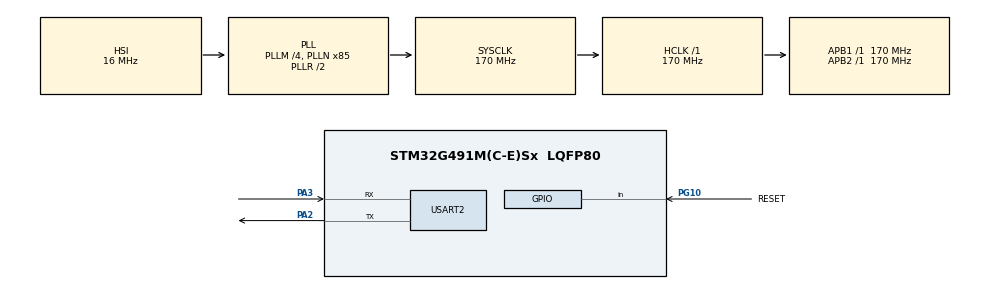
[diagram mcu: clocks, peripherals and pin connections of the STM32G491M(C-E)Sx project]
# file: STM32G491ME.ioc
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FREERTOS.Tasks01=defaultTask,0,192,StartDefaultTask,Default,NULL,Dynamic,NULL,NULL
FREERTOS.configMINIMAL_STACK_SIZE=192
FREERTOS.configTOTAL_HEAP_SIZE=65536
FREERTOS.configUSE_NEWLIB_REENTRANT=1
FREERTOS.configUSE_TIMERS=1
Mcu.Family=STM32G4
Mcu.Name=STM32G491M(C-E)Sx
Mcu.Package=LQFP80
NVIC.PriorityGroup=NVIC_PRIORITYGROUP_4
NVIC.TIM2_IRQn=true\:15\:0\:false\:false\:true\:false\:false\:true\:true
NVIC.TimeBase=TIM2_IRQn
NVIC.TimeBaseIP=TIM2
NVIC.USART2_IRQn=true\:5\:0\:false\:false\:true\:true\:true\:true\:true
PA13.Mode=Trace_Asynchronous_SW
PA13.Signal=SYS_JTMS-SWDIO
PA14.Mode=Trace_Asynchronous_SW
PA14.Signal=SYS_JTCK-SWCLK
PA2.Mode=Asynchronous
PA2.Signal=USART2_TX
PA3.Mode=Asynchronous
PA3.Signal=USART2_RX
PB3.Mode=Trace_Asynchronous_SW
PB3.Signal=SYS_JTDO-SWO
PG10-NRST.GPIO_Label=RESET
PG10-NRST.Signal=GPIO_Input
ProjectManager.HeapSize=0x200
ProjectManager.StackSize=0x400
ProjectManager.TargetToolchain=STM32CubeIDE
RCC.ADC12Freq_Value=170000000
RCC.ADC345Freq_Value=170000000
RCC.AHBFreq_Value=170000000
RCC.APB1Freq_Value=170000000
RCC.APB1TimFreq_Value=170000000
RCC.APB2Freq_Value=170000000
RCC.APB2TimFreq_Value=170000000
RCC.CortexFreq_Value=170000000
RCC.EXTERNAL_CLOCK_VALUE=12288000
RCC.HCLKFreq_Value=170000000
RCC.HSE_VALUE=32000000
RCC.HSI48_VALUE=48000000
RCC.HSI_VALUE=16000000
RCC.LSE_VALUE=32768
RCC.PLLM=RCC_PLLM_DIV4
RCC.PLLN=85
RCC.SYSCLKFreq_VALUE=170000000
RCC.SYSCLKSource=RCC_SYSCLKSOURCE_PLLCLK
RCC.VCOOutputFreq_Value=340000000
USART2.VirtualMode-Asynchronous=VM_ASYNC
VP_CRC_VS_CRC.Mode=CRC_Activate
VP_FREERTOS_VS_CMSIS_V1.Mode=CMSIS_V1
VP_SYS_VS_DBSignals.Mode=DisableDeadBatterySignals
VP_SYS_VS_tim2.Mode=TIM2
board=custom

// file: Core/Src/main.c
/* USER CODE BEGIN Header */
/**
  ******************************************************************************
  * @file           : main.c
  * @brief          : Main program body
  ******************************************************************************
  * @attention
  *
  * Copyright (c) 2026 STMicroelectronics.
  * All rights reserved.
  *
  * This software is licensed under terms that can be found in the LICENSE file
  * in the root directory of this software component.
  * If no LICENSE file comes with this software, it is provided AS-IS.
  *
  ******************************************************************************
  */
/* USER CODE END Header */
#include "main.h"
#include "cmsis_os.h"

/* USER CODE BEGIN Includes */
//#define USE_FULL_LL_DRIVER
/* USER CODE END Includes */

CRC_HandleTypeDef hcrc;

osThreadId defaultTaskHandle;

void SystemClock_Config(void);
static void MX_GPIO_Init(void);
static void MX_USART2_UART_Init(void);
static void MX_CRC_Init(void);
void StartDefaultTask(void const * argument);

int main(void)
{

  /* MCU Configuration--------------------------------------------------------*/

  /* Reset of all peripherals, Initializes the Flash interface and the Systick. */
  HAL_Init();

  /* Configure the system clock */
  SystemClock_Config();

  /* Initialize all configured peripherals */
  MX_GPIO_Init();
  MX_USART2_UART_Init();
  MX_CRC_Init();

  /* Create the thread(s) */
  /* definition and creation of defaultTask */
  osThreadDef(defaultTask, StartDefaultTask, osPriorityNormal, 0, 192);
  defaultTaskHandle = osThreadCreate(osThread(defaultTask), NULL);

  /* Start scheduler */
  osKernelStart();

  /* We should never get here as control is now taken by the scheduler */

  /* Infinite loop */
  while (1)
  {

  }
}

void SystemClock_Config(void)
{
  RCC_OscInitTypeDef RCC_OscInitStruct = {0};
  RCC_ClkInitTypeDef RCC_ClkInitStruct = {0};

  /** Configure the main internal regulator output voltage
  */
  HAL_PWREx_ControlVoltageScaling(PWR_REGULATOR_VOLTAGE_SCALE1_BOOST);

  /** Initializes the RCC Oscillators according to the specified parameters
  * in the RCC_OscInitTypeDef structure.
  */
  RCC_OscInitStruct.OscillatorType = RCC_OSCILLATORTYPE_HSI;
  RCC_OscInitStruct.HSIState = RCC_HSI_ON;
  RCC_OscInitStruct.HSICalibrationValue = RCC_HSICALIBRATION_DEFAULT;
  RCC_OscInitStruct.PLL.PLLState = RCC_PLL_ON;
  RCC_OscInitStruct.PLL.PLLSource = RCC_PLLSOURCE_HSI;
  RCC_OscInitStruct.PLL.PLLM = RCC_PLLM_DIV4;
  RCC_OscInitStruct.PLL.PLLN = 85;
  RCC_OscInitStruct.PLL.PLLP = RCC_PLLP_DIV2;
  RCC_OscInitStruct.PLL.PLLQ = RCC_PLLQ_DIV2;
  RCC_OscInitStruct.PLL.PLLR = RCC_PLLR_DIV2;
  if (HAL_RCC_OscConfig(&RCC_OscInitStruct) != HAL_OK)
  {
    Error_Handler();
  }

  /** Initializes the CPU, AHB and APB buses clocks
  */
  RCC_ClkInitStruct.ClockType = RCC_CLOCKTYPE_HCLK|RCC_CLOCKTYPE_SYSCLK
                              |RCC_CLOCKTYPE_PCLK1|RCC_CLOCKTYPE_PCLK2;
  RCC_ClkInitStruct.SYSCLKSource = RCC_SYSCLKSOURCE_PLLCLK;
  RCC_ClkInitStruct.AHBCLKDivider = RCC_SYSCLK_DIV1;
  RCC_ClkInitStruct.APB1CLKDivider = RCC_HCLK_DIV1;
  RCC_ClkInitStruct.APB2CLKDivider = RCC_HCLK_DIV1;

  if (HAL_RCC_ClockConfig(&RCC_ClkInitStruct, FLASH_LATENCY_4) != HAL_OK)
  {
    Error_Handler();
  }
}

static void MX_CRC_Init(void)
{

  hcrc.Instance = CRC;
  hcrc.Init.DefaultPolynomialUse = DEFAULT_POLYNOMIAL_ENABLE;
  hcrc.Init.DefaultInitValueUse = DEFAULT_INIT_VALUE_ENABLE;
  hcrc.Init.InputDataInversionMode = CRC_INPUTDATA_INVERSION_NONE;
  hcrc.Init.OutputDataInversionMode = CRC_OUTPUTDATA_INVERSION_DISABLE;
  hcrc.InputDataFormat = CRC_INPUTDATA_FORMAT_BYTES;
  if (HAL_CRC_Init(&hcrc) != HAL_OK)
  {
    Error_Handler();
  }

}

static void MX_USART2_UART_Init(void)
{

  LL_USART_InitTypeDef USART_InitStruct = {0};

  LL_GPIO_InitTypeDef GPIO_InitStruct = {0};
  RCC_PeriphCLKInitTypeDef PeriphClkInit = {0};

  /** Initializes the peripherals clocks
  */
  PeriphClkInit.PeriphClockSelection = RCC_PERIPHCLK_USART2;
  PeriphClkInit.Usart2ClockSelection = RCC_USART2CLKSOURCE_PCLK1;
  if (HAL_RCCEx_PeriphCLKConfig(&PeriphClkInit) != HAL_OK)
  {
    Error_Handler();
  }

  /* Peripheral clock enable */
  LL_APB1_GRP1_EnableClock(LL_APB1_GRP1_PERIPH_USART2);

  LL_AHB2_GRP1_EnableClock(LL_AHB2_GRP1_PERIPH_GPIOA);
  /**USART2 GPIO Configuration
  PA2   ------> USART2_TX
  PA3   ------> USART2_RX
  */
  GPIO_InitStruct.Pin = LL_GPIO_PIN_2;
  GPIO_InitStruct.Mode = LL_GPIO_MODE_ALTERNATE;
  GPIO_InitStruct.Speed = LL_GPIO_SPEED_FREQ_LOW;
  GPIO_InitStruct.OutputType = LL_GPIO_OUTPUT_PUSHPULL;
  GPIO_InitStruct.Pull = LL_GPIO_PULL_NO;
  GPIO_InitStruct.Alternate = LL_GPIO_AF_7;
  LL_GPIO_Init(GPIOA, &GPIO_InitStruct);

  GPIO_InitStruct.Pin = LL_GPIO_PIN_3;
  GPIO_InitStruct.Mode = LL_GPIO_MODE_ALTERNATE;
  GPIO_InitStruct.Speed = LL_GPIO_SPEED_FREQ_LOW;
  GPIO_InitStruct.OutputType = LL_GPIO_OUTPUT_PUSHPULL;
  GPIO_InitStruct.Pull = LL_GPIO_PULL_NO;
  GPIO_InitStruct.Alternate = LL_GPIO_AF_7;
  LL_GPIO_Init(GPIOA, &GPIO_InitStruct);

  /* USART2 interrupt Init */
  NVIC_SetPriority(USART2_IRQn, NVIC_EncodePriority(NVIC_GetPriorityGrouping(),5, 0));
  NVIC_EnableIRQ(USART2_IRQn);

  USART_InitStruct.PrescalerValue = LL_USART_PRESCALER_DIV1;
  USART_InitStruct.BaudRate = 115200;
  USART_InitStruct.DataWidth = LL_USART_DATAWIDTH_8B;
  USART_InitStruct.StopBits = LL_USART_STOPBITS_1;
  USART_InitStruct.Parity = LL_USART_PARITY_NONE;
  USART_InitStruct.TransferDirection = LL_USART_DIRECTION_TX_RX;
  USART_InitStruct.HardwareFlowControl = LL_USART_HWCONTROL_NONE;
  USART_InitStruct.OverSampling = LL_USART_OVERSAMPLING_16;
  LL_USART_Init(USART2, &USART_InitStruct);
  LL_USART_SetTXFIFOThreshold(USART2, LL_USART_FIFOTHRESHOLD_1_8);
  LL_USART_SetRXFIFOThreshold(USART2, LL_USART_FIFOTHRESHOLD_1_8);
  LL_USART_DisableFIFO(USART2);
  LL_USART_ConfigAsyncMode(USART2);

  LL_USART_Enable(USART2);

  /* Polling USART2 initialisation */
  while((!(LL_USART_IsActiveFlag_TEACK(USART2))) || (!(LL_USART_IsActiveFlag_REACK(USART2))))
  {
  }

}

static void MX_GPIO_Init(void)
{
  LL_GPIO_InitTypeDef GPIO_InitStruct = {0};

  /* GPIO Ports Clock Enable */
  LL_AHB2_GRP1_EnableClock(LL_AHB2_GRP1_PERIPH_GPIOG);
  LL_AHB2_GRP1_EnableClock(LL_AHB2_GRP1_PERIPH_GPIOA);
  LL_AHB2_GRP1_EnableClock(LL_AHB2_GRP1_PERIPH_GPIOB);

  /**/
  GPIO_InitStruct.Pin = RESET_Pin;
  GPIO_InitStruct.Mode = LL_GPIO_MODE_INPUT;
  GPIO_InitStruct.Pull = LL_GPIO_PULL_NO;
  LL_GPIO_Init(RESET_GPIO_Port, &GPIO_InitStruct);

}

void StartDefaultTask(void const * argument)
{
  for(;;)
  {
    osDelay(1);
  }
}

void HAL_TIM_PeriodElapsedCallback(TIM_HandleTypeDef *htim)
{
  if (htim->Instance == TIM2)
  {
    HAL_IncTick();
  }
}

void Error_Handler(void)
{
  __disable_irq();
  while (1)
  {
  }
}
